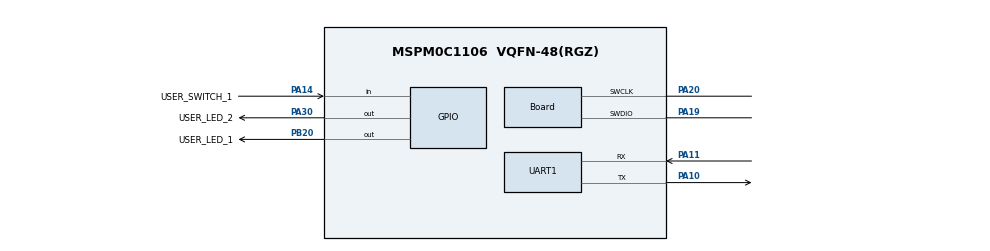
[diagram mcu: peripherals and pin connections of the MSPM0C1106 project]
//@cliArgs --device "MSPM0C1105_C1106" --package "VQFN-48(RGZ)" --part "Default"
//@v2CliArgs --device "MSPM0C1106" --package "VQFN-48(RGZ)"
// @cliArgs --board /ti/boards/LP_MSPM0C1106 --rtos nortos

/**
 * Import the modules used in this configuration.
 */
const GPIO          = scripting.addModule("/ti/driverlib/GPIO", {}, false);
const GPIO1         = GPIO.addInstance();
const GPIO2         = GPIO.addInstance();
const UART          = scripting.addModule("/ti/driverlib/UART", {}, false);
const UART1         = UART.addInstance();
const ProjectConfig = scripting.addModule("/ti/project_config/ProjectConfig");

/**
 * Write custom configuration values to the imported modules.
 */
GPIO1.$name                          = "GPIO_LEDS";
GPIO1.associatedPins.create(2);
GPIO1.associatedPins[0].$name        = "USER_LED_1";
GPIO1.associatedPins[0].assignedPort = "PORTB";
GPIO1.associatedPins[0].assignedPin  = "20";
GPIO1.associatedPins[0].pin.$assign  = "PB20";
GPIO1.associatedPins[1].$name        = "USER_LED_2";
GPIO1.associatedPins[1].assignedPort = "PORTA";
GPIO1.associatedPins[1].assignedPin  = "30";
GPIO1.associatedPins[1].pin.$assign  = "PA30";

const Board                       = scripting.addModule("/ti/driverlib/Board", {}, false);
Board.peripheral.$assign          = "DEBUGSS";
Board.peripheral.swclkPin.$assign = "PA20";
Board.peripheral.swdioPin.$assign = "PA19";

GPIO2.$name                              = "GPIO_SWITCHES";
GPIO2.associatedPins[0].direction        = "INPUT";
GPIO2.associatedPins[0].interruptEn      = true;
GPIO2.associatedPins[0].polarity         = "FALL";
GPIO2.associatedPins[0].internalResistor = "PULL_UP";
GPIO2.associatedPins[0].$name            = "USER_SWITCH_1";
GPIO2.associatedPins[0].assignedPort     = "PORTA";
GPIO2.associatedPins[0].assignedPin      = "14";
GPIO2.associatedPins[0].pin.$assign      = "PA14";

const SYSCTL              = scripting.addModule("/ti/driverlib/SYSCTL", {}, false);
SYSCTL.peripheral.$assign = "SYSCTL";

UART1.$name                    = "UART_0";
UART1.enabledInterrupts        = ["RX"];
UART1.peripheral.$assign       = "UART0";
UART1.peripheral.rxPin.$assign = "PA11";
UART1.peripheral.txPin.$assign = "PA10";

ProjectConfig.migrationCondition = true;
ProjectConfig.genLinker          = false;
scripting.suppress("All four File Generation options must be enabled in order to guarantee Device Migration support\\. If an option is disabled, the user must manually configure that setting on its own file\\.", ProjectConfig);
